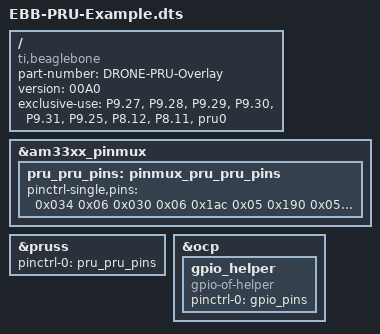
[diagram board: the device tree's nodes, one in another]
/* Device Tree Overlay for enabling the pins that are used in Chapter 13
* This overlay is based on the BB-PRU-01 overlay
* Written by Derek Molloy for the book "Exploring BeagleBone: Tools and 
* Techniques for Building with Embedded Linux" by John Wiley & Sons, 2014
* ISBN 9781118935125. Please see the file README.md in the repository root 
* directory for copyright and GNU GPLv3 license information.
*/
/dts-v1/;
/plugin/;

/ {
   compatible = "ti,beaglebone", "ti,beaglebone-black";

   part-number = "DRONE-PRU-Overlay";
   version = "00A0";

   /* This overlay uses the following resources */
   exclusive-use =
         "P9.27", "P9.28", "P9.29", "P9.30","P9.31","P9.25","P8.12","P8.11", "pru0";

   fragment@0 {
      target = <&am33xx_pinmux>;
      __overlay__ {

         pru_pru_pins: pinmux_pru_pru_pins {   // The PRU pin modes
            pinctrl-single,pins = <          
               0x034 0x06  // P8_11 pr1_pru0_pru_r30_15, MODE6 | OUTPUT | PRU
               0x030 0x06  // P8_12 pr1_pru0_pru_r30_14, MODE6 | OUTPUT | PRU
               0x1ac 0x05  // P9_25 pr1_pru0_pru_r30_7, MODE5 | OUTPUT | PRU
               0x190 0x05  // P9_31 pr1_pru0_pru_r30_0, MODE5 | OUTPUT | PRU

               0x1A4 0x26  // P9_27 pr1_pru0_pru_r31_5, MODE6 | INPUT | PRU
               0x19c 0x26  // P9_28 pr1_pru0_pru_r31_3, MODE6 | INPUT | PRU
               0x194 0x26  // P9_29 pr1_pru0_pru_r31_1 , MODE 6 | INPUT | PRU
               0x198 0x26  // P9_30 pr1_pru0_pru_r31_2 , MODE 6 | INPUT | PRU 

               //0x0A0 0x06  // P8_45 pr1_pru1_pru_r30_0, MODE5 | OUTPUT | PRU
               //0x0A4 0x05  // P8_46 pr1_pru1_pru_r30_1, MODE5 | OUTPUT | PRU
               //0x0A8 0x25  // P8_43 pr1_pru1_pru_r30_2, MODE5 | INPUT | PRU
            >;
         };
      };
   };

   fragment@1 {         // Enable the PRUSS
      target = <&pruss>;
      __overlay__ {
         status = "okay";
         pinctrl-names = "default";
         pinctrl-0 = <&pru_pru_pins>;
      };
   };

   fragment@2 {         // Enable the GPIOs
      target = <&ocp>;
      __overlay__ {
         gpio_helper {
            compatible = "gpio-of-helper";
            status = "okay";
            pinctrl-names = "default";
            pinctrl-0 = <&gpio_pins>;
         };
      };
   };
};
